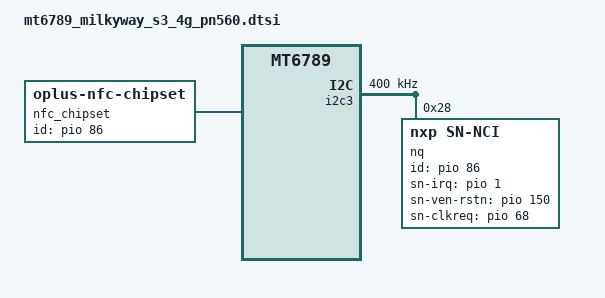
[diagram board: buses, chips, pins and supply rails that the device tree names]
/**********************************************************************************
* Copyright (c)  2008-2020  Guangdong oplus Mobile Comm Corp., Ltd
*
***********************************************************************************/
&odm {
	nfc_chipset:nfc_chipset {
		compatible = "oplus-nfc-chipset";
		mixed-chipset = <1>;
		id-gpio = <&pio 86 0x00>;
		id_count = <2>;
		id-0-key = <0>;
		id-0-value-chipset = "none";
		id-0-value-manifest-path = "/odm/etc/vintf/manifest_empty.xml";
		id-0-value-feature-path = "/odm/etc/feature_empty.xml";
		id-1-key = <1>;
		id-1-value-chipset = "PN560";
		id-1-value-manifest-path = "/odm/etc/vintf/manifest_dsnfc_pn560.xml";
		id-1-value-feature-path = "/odm/etc/com.oplus.nfc_feature_pn560.xml";
	};
};


&i2c3 {
       status = "okay";
       clock-frequency = <400000>;
       nq@28 {
               compatible = "nxp,sn-nci";
               mixed-chipset = <1>;
               id-gpio = <&pio 86 0x00>;
               id_count = <2>;
               id-0-key = <0>;
               id-0-value-chipset = "none";
               id-1-key = <1>;
               id-1-value-chipset = "PN560";
               reg = <0x28>;
               nxp,sn-irq = <&pio 1 0x0>;
               nxp,sn-ven-rstn = <&pio 150 0x0>;
               nxp,sn-clkreq = <&pio 68 0x0>;
               interrupt-parent = <&pio>;
       };
};
